# CAL0 register map
Vendor: Texas Instruments
Registers are 32-bit, read-write, reset 0x0 unless marked. A register's access mark holds for its fields unless they carry their own. Offsets are as the file gives them; [hi:lo] are bit positions; {n}, {i} and the like mark numbered series.

## CAL0 (part 2 of 2)
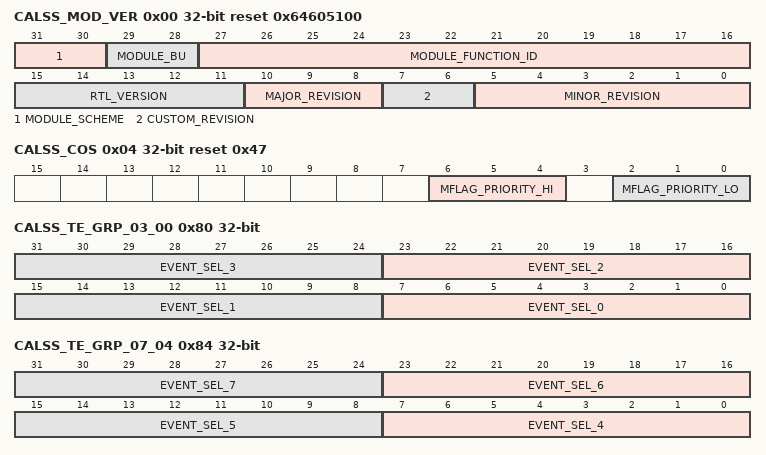
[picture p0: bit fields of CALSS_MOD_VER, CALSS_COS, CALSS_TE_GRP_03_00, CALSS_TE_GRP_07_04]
0x00 CALSS_MOD_VER ro reset 0x64605100 — The Module and Version Register identifies the module identifier and CAL_REVISION of the CAL module.
  [31:30] MODULE_SCHEME — CAL module Scheme
  [29:28] MODULE_BU — CAL module Bussiness Unit
  [27:16] MODULE_FUNCTION_ID — CAL module ID.
  [15:11] RTL_VERSION
  [10:8] MAJOR_REVISION
  [7:6] CUSTOM_REVISION
  [5:0] MINOR_REVISION
0x04 CALSS_COS reset 0x47 — The Class of Service register is used to set the priority of master transactions based on the state of ~imflag.
  [6:4] MFLAG_PRIORITY_HI — CAL Master hi priority value when mflag is set.
  [2:0] MFLAG_PRIORITY_LO — CAL Master low priority value when mflag is not set.
0x08 CALSS_VID_MUX_CTRL — Updated CALSS_VID_MUX_CTRL Register The Video Mux Control manages the video mux
  [2:0] BYS_MUX_SEL — CAL BYS in video mux control 4 - Selects LVDSRX output 1 7 - Selects LVDSRX output 4 Others - Reserved
0x18 CALSS_MODE reset 0x1 — The CAL Mode register controls CAL operational mode.
  [0] BASELINE_MODE — The BASELINE_MODE bit selects CAL operational mode. 0: Selects CAL full operational mode (YUV422 to YUV422BP conversion option enabled) 1: Selects CAL baseline mode (YUV422 to YUV422BP conversion option disabled)
0x80 CALSS_TE_GRP_03_00 — The Trace Event Group registers contains the Trace Event selection for a particular Trace Event group.
  [8n+7:8n] EVENT_SEL_{n} (n=0..3) — This field describes which Trace Event will be sent to trace_events[{n}]. See trace events for more info.
0x84 CALSS_TE_GRP_07_04 — The Trace Event Group registers contains the Trace Event selection for a particular Trace Event group.
  [8n-25:8n-32] EVENT_SEL_{n} (n=4..7) — This field describes which Trace Event will be sent to trace_events[{n}]. See trace events for more info.
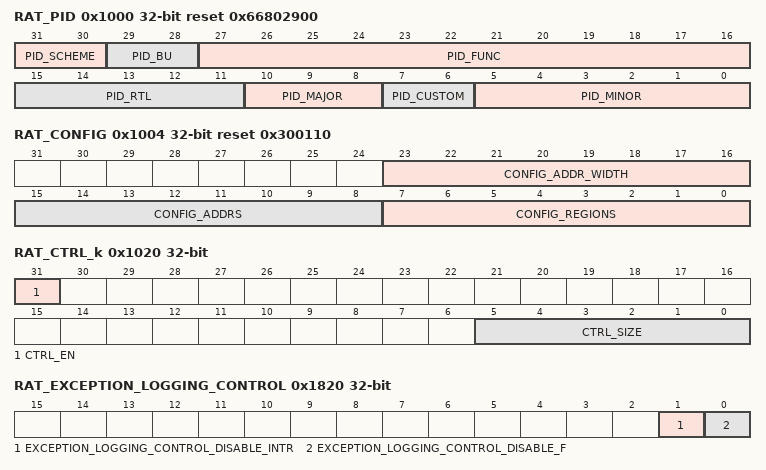
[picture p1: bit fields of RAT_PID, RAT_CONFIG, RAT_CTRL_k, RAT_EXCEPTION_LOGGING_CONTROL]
0x1000 RAT_PID ro reset 0x66802900 — The Revision Register contains the major and minor revisions for the module.
  [31:30] PID_SCHEME — PID register scheme
  [29:28] PID_BU — Business Unit: 10 = Processors
  [27:16] PID_FUNC — Module ID
  [15:11] PID_RTL — RTL REVISION. Will vary depending on release.
  [10:8] PID_MAJOR — Major REVISION
  [7:6] PID_CUSTOM — Custom
  [5:0] PID_MINOR — Minor REVISION
0x1004 RAT_CONFIG ro reset 0x300110 — The Config Register contains the configuration values for the module.
  [23:16] CONFIG_ADDR_WIDTH — Number of address bits
  [15:8] CONFIG_ADDRS — Number of addresses
  [7:0] CONFIG_REGIONS — Number of regions
0x1020 RAT_CTRL_k — The Control for Region a Offset = 1020h + (k * 10h); where k = 0h to Fh
  [31] CTRL_EN — Enable for the Region
  [5:0] CTRL_SIZE — Size of the Region in Address Bits. 0 = 1 byte, 1 = 2B, 2 = 4B, 3 = 8B, etc. up to 32 = 4GB.
0x1024 RAT_BASE_k — The Base Address for Region a. This is the source address for matching to a region. Offset = 1024h + (k * 10h); where k = 0h to Fh
  [31:0] BASE_BASE — Base Address for the Region. It must be aligned to the programmed size.
0x1028 RAT_TRANS_L_k — The Translated Lower Address Bits for Region a Offset = 1028h + (k * 10h); where k = 0h to Fh
  [31:0] TRANS_L_LOWER — Translated Lower Address Bits for the Region. It must be aligned to the programmed size.
0x102C RAT_TRANS_U_k — The Translated Upper Address Bits for Region a Offset = 102Ch + (k * 10h); where k = 0h to Fh
  [15:0] TRANS_U_UPPER — Translated Upper Address Bits for the Region
0x1804 RAT_DESTINATION_ID — The Destination ID Register defines the destination ID value for error messages.
  [7:0] DESTINATION_ID_DEST_ID — The destination ID.
0x1820 RAT_EXCEPTION_LOGGING_CONTROL — The Exception Logging Control Register controls the exception logging.
  [1] EXCEPTION_LOGGING_CONTROL_DISABLE_INTR — Disables logging interrupt when set.
  [0] EXCEPTION_LOGGING_CONTROL_DISABLE_F — Disables logging when set.
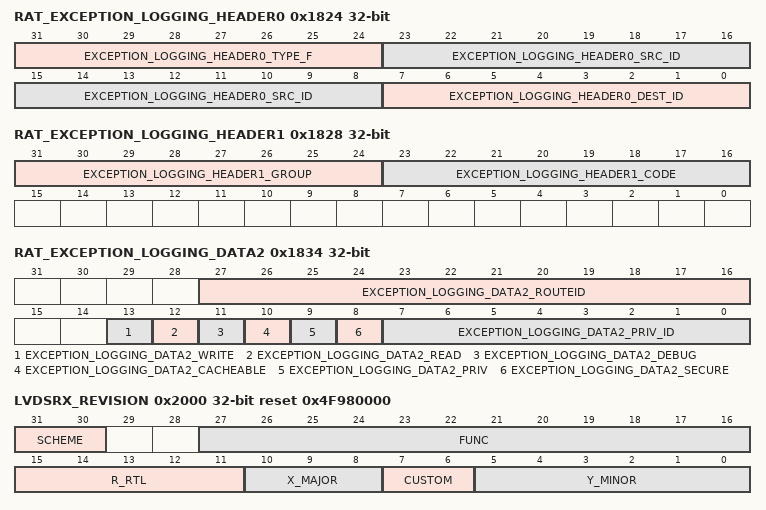
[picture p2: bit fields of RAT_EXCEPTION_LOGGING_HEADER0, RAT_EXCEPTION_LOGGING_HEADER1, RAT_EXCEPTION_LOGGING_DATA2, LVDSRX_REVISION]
0x1824 RAT_EXCEPTION_LOGGING_HEADER0 ro — The Exception Logging Header 0 Register contains the first word of the header.
  [31:24] EXCEPTION_LOGGING_HEADER0_TYPE_F — Type. 4 = RAT.
  [23:8] EXCEPTION_LOGGING_HEADER0_SRC_ID — Source ID.
  [7:0] EXCEPTION_LOGGING_HEADER0_DEST_ID — Destination ID.
0x1828 RAT_EXCEPTION_LOGGING_HEADER1 ro — The Exception Logging Header 1 Register contains the second word of the header.
  [31:24] EXCEPTION_LOGGING_HEADER1_GROUP — Group.
  [23:16] EXCEPTION_LOGGING_HEADER1_CODE — Code. 1 = Boundary crossing error.
0x182C RAT_EXCEPTION_LOGGING_DATA0 ro — The Exception Logging Data 0 Register contains the first word of the data.
  [31:0] EXCEPTION_LOGGING_DATA0_ADDR_L — Address lower 32 bits.
0x1830 RAT_EXCEPTION_LOGGING_DATA1 ro — The Exception Logging Data 1 Register contains the second word of the data.
  [15:0] EXCEPTION_LOGGING_DATA1_ADDR_H — Address upper 12 bits.
0x1834 RAT_EXCEPTION_LOGGING_DATA2 ro — The Exception Logging Data 2 Register contains the third word of the data.
  [27:16] EXCEPTION_LOGGING_DATA2_ROUTEID — Route ID.
  [13] EXCEPTION_LOGGING_DATA2_WRITE — Write.
  [12] EXCEPTION_LOGGING_DATA2_READ — Read.
  [11] EXCEPTION_LOGGING_DATA2_DEBUG — Debug.
  [10] EXCEPTION_LOGGING_DATA2_CACHEABLE — Cacheable.
  [9] EXCEPTION_LOGGING_DATA2_PRIV — Priv.
  [8] EXCEPTION_LOGGING_DATA2_SECURE — Secure.
  [7:0] EXCEPTION_LOGGING_DATA2_PRIV_ID — Priv ID.
0x1838 RAT_EXCEPTION_LOGGING_DATA3 ro — The Exception Logging Data 3 Register contains the fourth word of the data. Reading this register will clear the error pending bit.
  [9:0] EXCEPTION_LOGGING_DATA3_BYTECNT — Byte count.
0x1840 RAT_EXCEPTION_PEND_SET access not given — The Exception Logging Interrupt Pending Set Register allows to set the pend signal.
  [0] EXCEPTION_PEND_SET_PEND_SET — Write a 1 to set the exception pend signal. (access RW1S)
0x1844 RAT_EXCEPTION_PEND_CLEAR access not given — The Exception Logging Interrupt Pending Clear Register allows to clear the pend signal.
  [0] EXCEPTION_PEND_CLEAR_PEND_CLR — Write a 1 to clear the exception pend signal. (access RW1C)
0x1848 RAT_EXCEPTION_ENABLE_SET access not given — The Exception Logging Interrupt Enable Set Register allows to set the interrupt enable signal.
  [0] EXCEPTION_ENABLE_SET_ENABLE_SET — Write a 1 to set the exception interrupt enable signal. (access RW1S)
0x184C RAT_EXCEPTION_ENABLE_CLEAR access not given — The Exception Logging Interrupt Enable Clear Register allows to clear the interrupt enable signal.
  [0] EXCEPTION_ENABLE_CLEAR_ENABLE_CLR — Write a 1 to clear the exception interrupt enable signal. (access RW1C)
0x1850 RAT_EOI_REG — EOI Register The EOI register is used to re-trigger the pulse interrupt signal to ensure that any nested interrupt events are serviced. The software interrupt handler must write to the EOI register at the end of the current interrupt processing routine, so that new events can re-trigger the pulse interrupt signal again. For level interrupt signals the EOI register is not functional and must not be used.
  [15:0] EOI_REG_EOI_WR — EOI Register
0x2000 LVDSRX_REVISION ro reset 0x4F980000
  [31:30] SCHEME — Used to distinguish between old scheme and current. RD: 0 - LEGACY : Legacy ASP or WTBU scheme RD: 1 - H08 : Highlander 0.8 scheme
  [27:16] FUNC — Function indicates a software compatible module family. If there is no level of software compatibility a new Func number (and hence REVISION) should be assigned.
  [15:11] R_RTL — RTL Version (R), maintained by IP design owner. RTL follows a numbering such as X.Y.R.Z which are explained in this table. R changes ONLY when: (1) PDS uploads occur which may have been due to spec changes (2) Bug fixes occur (3) Resets to '0' when X or Y changes. Design team has an internal 'Z' (customer invisible) number which increments on every drop that happens due to DV and RTL updates. Z resets to 0 when R increments.
  [10:8] X_MAJOR — Major Revision (X), maintained by IP specification owner. X changes ONLY when: (1) There is a major feature addition. An example would be adding Master Mode to Utopia Level2. The Func field (or Class/Type in old PID format) will remain the same. X does NOT change due to: (1) Bug fixes (2) Change in feature parameters.
  [7:6] CUSTOM — Indicates a special version for a particular device. Consequence of use may avoid use of standard Chip Support Library (CSL) / Drivers. STANDARD Non custom (standard) REVISION RD: 0 - STANDARD : Non custom (standard) REVISION
  [5:0] Y_MINOR
0x2010 LVDSRX_SYSCONFIG
  [0] RESERVED — RD: 0 - DONE : Reset done, no pending action WR: 0 - NOACTION : No action WR: 1 - RESET : Initiate software reset RD: 1 - PENDING : Reset (software or other) ongoing
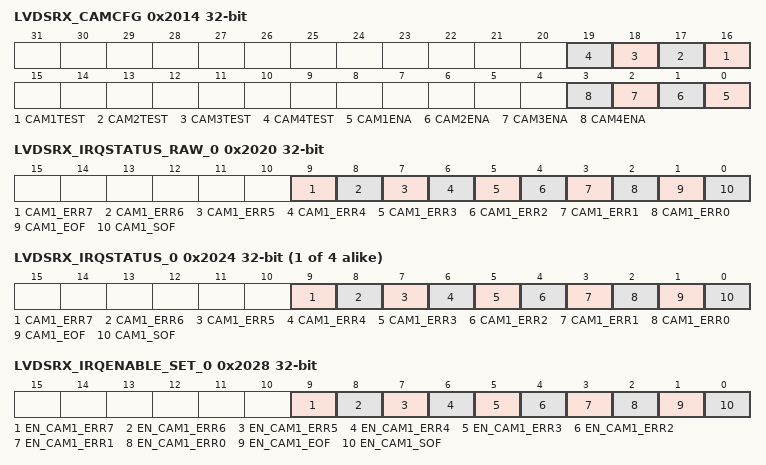
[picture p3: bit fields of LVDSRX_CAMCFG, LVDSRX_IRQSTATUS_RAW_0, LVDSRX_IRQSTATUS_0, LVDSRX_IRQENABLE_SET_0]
0x2014 LVDSRX_CAMCFG
  [n+15] CAM{n}TEST (n=1..4) — Camera port #{n} monitor
  [n-1] CAM{n}ENA (n=1..4) — Camera port #{n} control
0x201C LVDSRX_IRQ_EOI wo — The EOI register is used to re-trigger the pulse interrupt signal to ensure that any nested interrupt events are serviced. The software interrupt handler must write to the EOI register at the end of the current interrupt processing routine, so that new events can re-trigger the pulse interrupt signal again. For level interrupt signals the EOI register is not functional and must not be used.
  [2:0] LINE_NUMBER — Software End Of Interrupt (EOI) control. Write number of interrupt output to force re-evaluation of associated pending interrupts. Write n: EOI for interrupt output associated with EOI #n. WR:1 - EOI1 : EOI for interrupt output line #1 RD:0 - READ0 : Reads always 0 (no EOI memory) WR:2 - EOI2 : EOI for interrupt output line #2 WR:3 - EOI3 : EOI for interrupt output line #3 WR:4 - EOI4 : EOI for interrupt output line #4
0x2020 LVDSRX_IRQSTATUS_RAW_0 access not given
  [9] CAM1_ERR7 — sync detected timeout reached RD: 0 - NOEVENT : No event pending RD: 1 - PENDING : Event pending (access RW1S)
  [8] CAM1_ERR6 — CRC error RD: 0 - NOEVENT : No event pending RD: 1 - PENDING : Event pending (access RW1S)
  [7] CAM1_ERR5 — unexpected SOF RD: 0 - NOEVENT : No event pending RD: 1 - PENDING : Event pending (access RW1S)
  [6] CAM1_ERR4 — unexpected SOL RD: 0 - NOEVENT : No event pending RD: 1 - PENDING : Event pending (access RW1S)
  [5] CAM1_ERR3 — unexpected EOF RD: 0 - NOEVENT : No event pending RD: 1 - PENDING : Event pending (access RW1S)
  [4] CAM1_ERR2 — unexpected EOL RD: 0 - NOEVENT : No event pending RD: 1 - PENDING : Event pending (access RW1S)
  [3] CAM1_ERR1 — unexpected SOV RD: 0 - NOEVENT : No event pending RD: 1 - PENDING : Event pending (access RW1S)
  [2] CAM1_ERR0 — EOX not received RD: 0 - NOEVENT : No event pending RD: 1 - PENDING : Event pending (access RW1S)
  [1] CAM1_EOF — End of frame timing RD: 0 - NOEVENT : No event pending RD: 1 - PENDING : Event pending (access RW1S)
  [0] CAM1_SOF — Start of frame timing RD: 0 - NOEVENT : No event pending RD: 1 - PENDING : Event pending (access RW1S)
{0x2024+0x10*i} LVDSRX_IRQSTATUS_{i} access not given (i=0..3)
  [9] CAM{i+1}_ERR7 — sync detected timeout reached RD: 0 - NOEVENT : No event pending RD: 1 - PENDING : Event pending (access RW1C)
  [8] CAM{i+1}_ERR6 — CRC error RD: 0 - NOEVENT : No event pending RD: 1 - PENDING : Event pending (access RW1C)
  [7] CAM{i+1}_ERR5 — unexpected SOF RD: 0 - NOEVENT : No event pending RD: 1 - PENDING : Event pending (access RW1C)
  [6] CAM{i+1}_ERR4 — unexpected SOL RD: 0 - NOEVENT : No event pending RD: 1 - PENDING : Event pending (access RW1C)
  [5] CAM{i+1}_ERR3 — unexpected EOF RD: 0 - NOEVENT : No event pending RD: 1 - PENDING : Event pending (access RW1C)
  [4] CAM{i+1}_ERR2 — unexpected EOL RD: 0 - NOEVENT : No event pending RD: 1 - PENDING : Event pending (access RW1C)
  [3] CAM{i+1}_ERR1 — unexpected SOV RD: 0 - NOEVENT : No event pending RD: 1 - PENDING : Event pending (access RW1C)
  [2] CAM{i+1}_ERR0 — EOX not received RD: 0 - NOEVENT : No event pending RD: 1 - PENDING : Event pending (access RW1C)
  [1] CAM{i+1}_EOF — End of frame timing RD: 0 - NOEVENT : No event pending RD: 1 - PENDING : Event pending (access RW1C)
  [0] CAM{i+1}_SOF — Start of frame timing RD: 0 - NOEVENT : No event pending RD: 1 - PENDING : Event pending (access RW1C)
0x2028 LVDSRX_IRQENABLE_SET_0 access not given
  [9] EN_CAM1_ERR7 — sync detected timeout reached WR: 0 - NOACTION : No action RD: 0 - DISABLED : Interrupt disabled (masked) RD: 1 - ENABLED : Interrupt enabled WR: 1 - ENABLE : Enable interrupt (access RW1S)
  [8] EN_CAM1_ERR6 — CRC error WR: 0 - NOACTION : No action RD: 0 - DISABLED : Interrupt disabled (masked) RD: 1 - ENABLED : Interrupt enabled WR: 1 - ENABLE : Enable interrupt (access RW1S)
  [7] EN_CAM1_ERR5 — unexpected SOF WR: 0 - NOACTION : No action RD: 0 - DISABLED : Interrupt disabled (masked) RD: 1 - ENABLED : Interrupt enabled WR: 1 - ENABLE : Enable interrupt (access RW1S)
  [6] EN_CAM1_ERR4 — unexpected SOL WR: 0 - NOACTION : No action RD: 0 - DISABLED : Interrupt disabled (masked) RD: 1 - ENABLED : Interrupt enabled WR: 1 - ENABLE : Enable interrupt (access RW1S)
  [5] EN_CAM1_ERR3 — unexpected EOF WR: 0 - NOACTION : No action RD: 0 - DISABLED : Interrupt disabled (masked) RD: 1 - ENABLED : Interrupt enabled WR: 1 - ENABLE : Enable interrupt (access RW1S)
  [4] EN_CAM1_ERR2 — unexpected EOL WR: 0 - NOACTION : No action RD: 0 - DISABLED : Interrupt disabled (masked) RD: 1 - ENABLED : Interrupt enabled WR: 1 - ENABLE : Enable interrupt (access RW1S)
  [3] EN_CAM1_ERR1 — unexpected SOV WR: 0 - NOACTION : No action RD: 0 - DISABLED : Interrupt disabled (masked) RD: 1 - ENABLED : Interrupt enabled WR: 1 - ENABLE : Enable interrupt (access RW1S)
  [2] EN_CAM1_ERR0 — EOX not received WR: 0 - NOACTION : No action RD: 0 - DISABLED : Interrupt disabled (masked) RD: 1 - ENABLED : Interrupt enabled WR: 1 - ENABLE : Enable interrupt (access RW1S)
  [1] EN_CAM1_EOF — End of frame timing WR: 0 - NOACTION : No action RD: 0 - DISABLED : Interrupt disabled (masked) RD: 1 - ENABLED : Interrupt enabled WR: 1 - ENABLE : Enable interrupt (access RW1S)
  [0] EN_CAM1_SOF — Start of frame timing WR: 0 - NOACTION : No action RD: 0 - DISABLED : Interrupt disabled (masked) RD: 1 - ENABLED : Interrupt enabled WR: 1 - ENABLE : Enable interrupt (access RW1S)
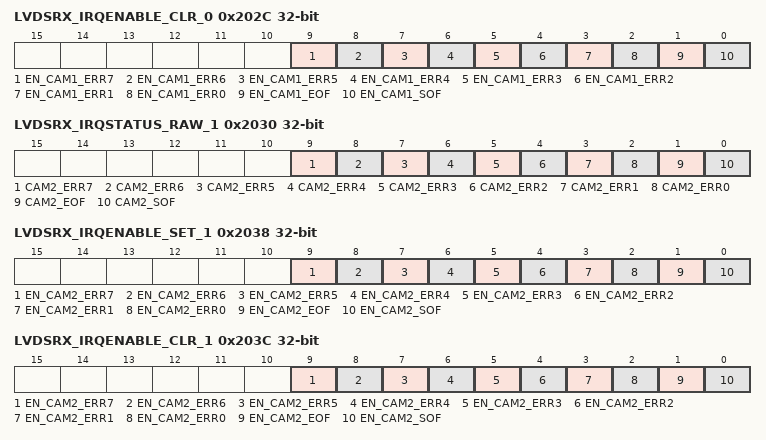
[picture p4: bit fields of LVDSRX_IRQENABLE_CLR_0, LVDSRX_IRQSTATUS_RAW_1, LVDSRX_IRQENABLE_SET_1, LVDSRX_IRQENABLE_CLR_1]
0x202C LVDSRX_IRQENABLE_CLR_0 access not given
  [9] EN_CAM1_ERR7 — sync detected timeout reached WR: 0 - NOACTION : No action RD: 0 - DISABLED : Interrupt disabled (masked) RD: 1 - ENABLED : Interrupt enabled WR: 1 - DISABLE : Disable interrupt (access RW1C)
  [8] EN_CAM1_ERR6 — CRC error WR: 0 - NOACTION : No action RD: 0 - DISABLED : Interrupt disabled (masked) RD: 1 - ENABLED : Interrupt enabled WR: 1 - DISABLE : Disable interrupt (access RW1C)
  [7] EN_CAM1_ERR5 — unexpected SOF WR: 0 - NOACTION : No action RD: 0 - DISABLED : Interrupt disabled (masked) RD: 1 - ENABLED : Interrupt enabled WR: 1 - DISABLE : Disable interrupt (access RW1C)
  [6] EN_CAM1_ERR4 — unexpected SOL WR: 0 - NOACTION : No action RD: 0 - DISABLED : Interrupt disabled (masked) RD: 1 - ENABLED : Interrupt enabled WR: 1 - DISABLE : Disable interrupt (access RW1C)
  [5] EN_CAM1_ERR3 — unexpected EOF WR: 0 - NOACTION : No action RD: 0 - DISABLED : Interrupt disabled (masked) RD: 1 - ENABLED : Interrupt enabled WR: 1 - DISABLE : Disable interrupt (access RW1C)
  [4] EN_CAM1_ERR2 — unexpected EOL WR: 0 - NOACTION : No action RD: 0 - DISABLED : Interrupt disabled (masked) RD: 1 - ENABLED : Interrupt enabled WR: 1 - DISABLE : Disable interrupt (access RW1C)
  [3] EN_CAM1_ERR1 — unexpected SOV WR: 0 - NOACTION : No action RD: 0 - DISABLED : Interrupt disabled (masked) RD: 1 - ENABLED : Interrupt enabled WR: 1 - DISABLE : Disable interrupt (access RW1C)
  [2] EN_CAM1_ERR0 — EOX not received WR: 0 - NOACTION : No action RD: 0 - DISABLED : Interrupt disabled (masked) RD: 1 - ENABLED : Interrupt enabled WR: 1 - DISABLE : Disable interrupt (access RW1C)
  [1] EN_CAM1_EOF — End of frame timing WR: 0 - NOACTION : No action RD: 0 - DISABLED : Interrupt disabled (masked) RD: 1 - ENABLED : Interrupt enabled WR: 1 - DISABLE : Disable interrupt (access RW1C)
  [0] EN_CAM1_SOF — Start of frame timing WR: 0 - NOACTION : No action RD: 0 - DISABLED : Interrupt disabled (masked) RD: 1 - ENABLED : Interrupt enabled WR: 1 - DISABLE : Disable interrupt (access RW1C)
0x2030 LVDSRX_IRQSTATUS_RAW_1 access not given
  [9] CAM2_ERR7 — sync detected timeout reached RD: 0 - NOEVENT : No event pending RD: 1 - PENDING : Event pending (access RW1S)
  [8] CAM2_ERR6 — CRC error RD: 0 - NOEVENT : No event pending RD: 1 - PENDING : Event pending (access RW1S)
  [7] CAM2_ERR5 — unexpected SOF RD: 0 - NOEVENT : No event pending RD: 1 - PENDING : Event pending (access RW1S)
  [6] CAM2_ERR4 — unexpected SOL RD: 0 - NOEVENT : No event pending RD: 1 - PENDING : Event pending (access RW1S)
  [5] CAM2_ERR3 — unexpected EOF RD: 0 - NOEVENT : No event pending RD: 1 - PENDING : Event pending (access RW1S)
  [4] CAM2_ERR2 — unexpected EOL RD: 0 - NOEVENT : No event pending RD: 1 - PENDING : Event pending (access RW1S)
  [3] CAM2_ERR1 — unexpected SOV RD: 0 - NOEVENT : No event pending RD: 1 - PENDING : Event pending (access RW1S)
  [2] CAM2_ERR0 — EOX not received RD: 0 - NOEVENT : No event pending RD: 1 - PENDING : Event pending (access RW1S)
  [1] CAM2_EOF — End of frame timing RD: 0 - NOEVENT : No event pending RD: 1 - PENDING : Event pending (access RW1S)
  [0] CAM2_SOF — Start of frame timing RD: 0 - NOEVENT : No event pending RD: 1 - PENDING : Event pending (access RW1S)
0x2038 LVDSRX_IRQENABLE_SET_1 access not given
  [9] EN_CAM2_ERR7 — sync detected timeout reached WR: 0 - NOACTION : No action RD: 0 - DISABLED : Interrupt disabled (masked) RD: 1 - ENABLED : Interrupt enabled WR: 1 - ENABLE : Enable interrupt (access RW1S)
  [8] EN_CAM2_ERR6 — CRC error WR: 0 - NOACTION : No action RD: 0 - DISABLED : Interrupt disabled (masked) RD: 1 - ENABLED : Interrupt enabled WR: 1 - ENABLE : Enable interrupt (access RW1S)
  [7] EN_CAM2_ERR5 — unexpected SOF WR: 0 - NOACTION : No action RD: 0 - DISABLED : Interrupt disabled (masked) RD: 1 - ENABLED : Interrupt enabled WR: 1 - ENABLE : Enable interrupt (access RW1S)
  [6] EN_CAM2_ERR4 — unexpected SOL WR: 0 - NOACTION : No action RD: 0 - DISABLED : Interrupt disabled (masked) RD: 1 - ENABLED : Interrupt enabled WR: 1 - ENABLE : Enable interrupt (access RW1S)
  [5] EN_CAM2_ERR3 — unexpected EOF WR: 0 - NOACTION : No action RD: 0 - DISABLED : Interrupt disabled (masked) RD: 1 - ENABLED : Interrupt enabled WR: 1 - ENABLE : Enable interrupt (access RW1S)
  [4] EN_CAM2_ERR2 — unexpected EOL WR: 0 - NOACTION : No action RD: 0 - DISABLED : Interrupt disabled (masked) RD: 1 - ENABLED : Interrupt enabled WR: 1 - ENABLE : Enable interrupt (access RW1S)
  [3] EN_CAM2_ERR1 — unexpected SOV WR: 0 - NOACTION : No action RD: 0 - DISABLED : Interrupt disabled (masked) RD: 1 - ENABLED : Interrupt enabled WR: 1 - ENABLE : Enable interrupt (access RW1S)
  [2] EN_CAM2_ERR0 — EOX not received WR: 0 - NOACTION : No action RD: 0 - DISABLED : Interrupt disabled (masked) RD: 1 - ENABLED : Interrupt enabled WR: 1 - ENABLE : Enable interrupt (access RW1S)
  [1] EN_CAM2_EOF — End of frame timing WR: 0 - NOACTION : No action RD: 0 - DISABLED : Interrupt disabled (masked) RD: 1 - ENABLED : Interrupt enabled WR: 1 - ENABLE : Enable interrupt (access RW1S)
  [0] EN_CAM2_SOF — Start of frame timing WR: 0 - NOACTION : No action RD: 0 - DISABLED : Interrupt disabled (masked) RD: 1 - ENABLED : Interrupt enabled WR: 1 - ENABLE : Enable interrupt (access RW1S)
0x203C LVDSRX_IRQENABLE_CLR_1 access not given
  [9] EN_CAM2_ERR7 — sync detected timeout reached WR: 0 - NOACTION : No action RD: 0 - DISABLED : Interrupt disabled (masked) RD: 1 - ENABLED : Interrupt enabled WR: 1 - DISABLE : Disable interrupt (access RW1C)
  [8] EN_CAM2_ERR6 — CRC error WR: 0 - NOACTION : No action RD: 0 - DISABLED : Interrupt disabled (masked) RD: 1 - ENABLED : Interrupt enabled WR: 1 - DISABLE : Disable interrupt (access RW1C)
  [7] EN_CAM2_ERR5 — unexpected SOF WR: 0 - NOACTION : No action RD: 0 - DISABLED : Interrupt disabled (masked) RD: 1 - ENABLED : Interrupt enabled WR: 1 - DISABLE : Disable interrupt (access RW1C)
  [6] EN_CAM2_ERR4 — unexpected SOL WR: 0 - NOACTION : No action RD: 0 - DISABLED : Interrupt disabled (masked) RD: 1 - ENABLED : Interrupt enabled WR: 1 - DISABLE : Disable interrupt (access RW1C)
  [5] EN_CAM2_ERR3 — unexpected EOF WR: 0 - NOACTION : No action RD: 0 - DISABLED : Interrupt disabled (masked) RD: 1 - ENABLED : Interrupt enabled WR: 1 - DISABLE : Disable interrupt (access RW1C)
  [4] EN_CAM2_ERR2 — unexpected EOL WR: 0 - NOACTION : No action RD: 0 - DISABLED : Interrupt disabled (masked) RD: 1 - ENABLED : Interrupt enabled WR: 1 - DISABLE : Disable interrupt (access RW1C)
  [3] EN_CAM2_ERR1 — unexpected SOV WR: 0 - NOACTION : No action RD: 0 - DISABLED : Interrupt disabled (masked) RD: 1 - ENABLED : Interrupt enabled WR: 1 - DISABLE : Disable interrupt (access RW1C)
  [2] EN_CAM2_ERR0 — EOX not received WR: 0 - NOACTION : No action RD: 0 - DISABLED : Interrupt disabled (masked) RD: 1 - ENABLED : Interrupt enabled WR: 1 - DISABLE : Disable interrupt (access RW1C)
  [1] EN_CAM2_EOF — End of frame timing WR: 0 - NOACTION : No action RD: 0 - DISABLED : Interrupt disabled (masked) RD: 1 - ENABLED : Interrupt enabled WR: 1 - DISABLE : Disable interrupt (access RW1C)
  [0] EN_CAM2_SOF — Start of frame timing WR: 0 - NOACTION : No action RD: 0 - DISABLED : Interrupt disabled (masked) RD: 1 - ENABLED : Interrupt enabled WR: 1 - DISABLE : Disable interrupt (access RW1C)
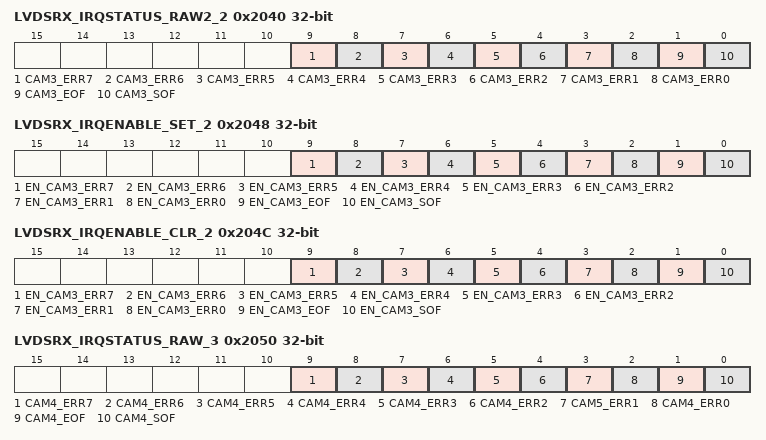
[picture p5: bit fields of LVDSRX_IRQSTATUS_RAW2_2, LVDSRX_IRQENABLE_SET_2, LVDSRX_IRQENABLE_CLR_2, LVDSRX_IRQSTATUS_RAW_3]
0x2040 LVDSRX_IRQSTATUS_RAW2_2 access not given
  [9] CAM3_ERR7 — sync detected timeout reached RD: 0 - NOEVENT : No event pending RD: 1 - PENDING : Event pending (access RW1S)
  [8] CAM3_ERR6 — CRC error RD: 0 - NOEVENT : No event pending RD: 1 - PENDING : Event pending (access RW1S)
  [7] CAM3_ERR5 — unexpected SOF RD: 0 - NOEVENT : No event pending RD: 1 - PENDING : Event pending (access RW1S)
  [6] CAM3_ERR4 — unexpected SOL RD: 0 - NOEVENT : No event pending RD: 1 - PENDING : Event pending (access RW1S)
  [5] CAM3_ERR3 — unexpected EOF RD: 0 - NOEVENT : No event pending RD: 1 - PENDING : Event pending (access RW1S)
  [4] CAM3_ERR2 — unexpected EOL RD: 0 - NOEVENT : No event pending RD: 1 - PENDING : Event pending (access RW1S)
  [3] CAM3_ERR1 — unexpected SOV RD: 0 - NOEVENT : No event pending RD: 1 - PENDING : Event pending (access RW1S)
  [2] CAM3_ERR0 — EOX not received RD: 0 - NOEVENT : No event pending RD: 1 - PENDING : Event pending (access RW1S)
  [1] CAM3_EOF — End of frame timing RD: 0 - NOEVENT : No event pending RD: 1 - PENDING : Event pending (access RW1S)
  [0] CAM3_SOF — Start of frame timing RD: 0 - NOEVENT : No event pending RD: 1 - PENDING : Event pending (access RW1S)
0x2048 LVDSRX_IRQENABLE_SET_2 access not given
  [9] EN_CAM3_ERR7 — sync detected timeout reached WR: 0 - NOACTION : No action RD: 0 - DISABLED : Interrupt disabled (masked) RD: 1 - ENABLED : Interrupt enabled WR: 1 - ENABLE : Enable interrupt (access RW1S)
  [8] EN_CAM3_ERR6 — CRC error WR: 0 - NOACTION : No action RD: 0 - DISABLED : Interrupt disabled (masked) RD: 1 - ENABLED : Interrupt enabled WR: 1 - ENABLE : Enable interrupt (access RW1S)
  [7] EN_CAM3_ERR5 — unexpected SOF WR: 0 - NOACTION : No action RD: 0 - DISABLED : Interrupt disabled (masked) RD: 1 - ENABLED : Interrupt enabled WR: 1 - ENABLE : Enable interrupt (access RW1S)
  [6] EN_CAM3_ERR4 — unexpected SOL WR: 0 - NOACTION : No action RD: 0 - DISABLED : Interrupt disabled (masked) RD: 1 - ENABLED : Interrupt enabled WR: 1 - ENABLE : Enable interrupt (access RW1S)
  [5] EN_CAM3_ERR3 — unexpected EOF WR: 0 - NOACTION : No action RD: 0 - DISABLED : Interrupt disabled (masked) RD: 1 - ENABLED : Interrupt enabled WR: 1 - ENABLE : Enable interrupt (access RW1S)
  [4] EN_CAM3_ERR2 — unexpected EOL WR: 0 - NOACTION : No action RD: 0 - DISABLED : Interrupt disabled (masked) RD: 1 - ENABLED : Interrupt enabled WR: 1 - ENABLE : Enable interrupt (access RW1S)
  [3] EN_CAM3_ERR1 — unexpected SOV WR: 0 - NOACTION : No action RD: 0 - DISABLED : Interrupt disabled (masked) RD: 1 - ENABLED : Interrupt enabled WR: 1 - ENABLE : Enable interrupt (access RW1S)
  [2] EN_CAM3_ERR0 — EOX not received WR: 0 - NOACTION : No action RD: 0 - DISABLED : Interrupt disabled (masked) RD: 1 - ENABLED : Interrupt enabled WR: 1 - ENABLE : Enable interrupt (access RW1S)
  [1] EN_CAM3_EOF — End of frame timing RD: 0 - NOEVENT : No event pending RD: 1 - PENDING : Event pending (access RW1S)
  [0] EN_CAM3_SOF — Start of frame timing WR: 0 - NOACTION : No action RD: 0 - DISABLED : Interrupt disabled (masked) RD: 1 - ENABLED : Interrupt enabled WR: 1 - ENABLE : Enable interrupt (access RW1S)
0x204C LVDSRX_IRQENABLE_CLR_2 access not given
  [9] EN_CAM3_ERR7 — sync detected timeout reached WR: 0 - NOACTION : No action RD: 0 - DISABLED : Interrupt disabled (masked) RD: 1 - ENABLED : Interrupt enabled WR: 1 - DISABLE : Disable interrupt (access RW1C)
  [8] EN_CAM3_ERR6 — CRC error WR: 0 - NOACTION : No action RD: 0 - DISABLED : Interrupt disabled (masked) RD: 1 - ENABLED : Interrupt enabled WR: 1 - DISABLE : Disable interrupt (access RW1C)
  [7] EN_CAM3_ERR5 — unexpected SOF WR: 0 - NOACTION : No action RD: 0 - DISABLED : Interrupt disabled (masked) RD: 1 - ENABLED : Interrupt enabled WR: 1 - DISABLE : Disable interrupt (access RW1C)
  [6] EN_CAM3_ERR4 — unexpected SOL WR: 0 - NOACTION : No action RD: 0 - DISABLED : Interrupt disabled (masked) RD: 1 - ENABLED : Interrupt enabled WR: 1 - DISABLE : Disable interrupt (access RW1C)
  [5] EN_CAM3_ERR3 — unexpected EOF WR: 0 - NOACTION : No action RD: 0 - DISABLED : Interrupt disabled (masked) RD: 1 - ENABLED : Interrupt enabled WR: 1 - DISABLE : Disable interrupt (access RW1C)
  [4] EN_CAM3_ERR2 — unexpected EOL WR: 0 - NOACTION : No action RD: 0 - DISABLED : Interrupt disabled (masked) RD: 1 - ENABLED : Interrupt enabled WR: 1 - DISABLE : Disable interrupt (access RW1C)
  [3] EN_CAM3_ERR1 — unexpected SOV WR: 0 - NOACTION : No action RD: 0 - DISABLED : Interrupt disabled (masked) RD: 1 - ENABLED : Interrupt enabled WR: 1 - DISABLE : Disable interrupt (access RW1C)
  [2] EN_CAM3_ERR0 — EOX not received WR: 0 - NOACTION : No action RD: 0 - DISABLED : Interrupt disabled (masked) RD: 1 - ENABLED : Interrupt enabled WR: 1 - DISABLE : Disable interrupt (access RW1C)
  [1] EN_CAM3_EOF — End of frame timing RD: 0 - NOEVENT : No event pending RD: 1 - PENDING : Event pending (access RW1C)
  [0] EN_CAM3_SOF — Start of frame timing WR: 0 - NOACTION : No action RD: 0 - DISABLED : Interrupt disabled (masked) RD: 1 - ENABLED : Interrupt enabled WR: 1 - DISABLE : Disable interrupt (access RW1C)
0x2050 LVDSRX_IRQSTATUS_RAW_3 access not given
  [9] CAM4_ERR7 — sync detected timeout reached RD: 0 - NOEVENT : No event pending RD: 1 - PENDING : Event pending (access RW1S)
  [8] CAM4_ERR6 — CRC error RD: 0 - NOEVENT : No event pending RD: 1 - PENDING : Event pending (access RW1S)
  [7] CAM4_ERR5 — unexpected SOF RD: 0 - NOEVENT : No event pending RD: 1 - PENDING : Event pending (access RW1S)
  [6] CAM4_ERR4 — unexpected SOL RD: 0 - NOEVENT : No event pending RD: 1 - PENDING : Event pending (access RW1S)
  [5] CAM4_ERR3 — unexpected EOF RD: 0 - NOEVENT : No event pending RD: 1 - PENDING : Event pending (access RW1S)
  [4] CAM4_ERR2 — unexpected EOL RD: 0 - NOEVENT : No event pending RD: 1 - PENDING : Event pending (access RW1S)
  [3] CAM5_ERR1 — unexpected SOV RD: 0 - NOEVENT : No event pending RD: 1 - PENDING : Event pending (access RW1S)
  [2] CAM4_ERR0 — EOX not received RD: 0 - NOEVENT : No event pending RD: 1 - PENDING : Event pending (access RW1S)
  [1] CAM4_EOF — End of frame timing RD: 0 - NOEVENT : No event pending RD: 1 - PENDING : Event pending (access RW1S)
  [0] CAM4_SOF — Start of frame timing RD: 0 - NOEVENT : No event pending RD: 1 - PENDING : Event pending (access RW1S)
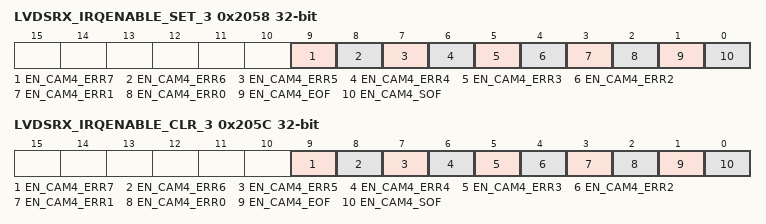
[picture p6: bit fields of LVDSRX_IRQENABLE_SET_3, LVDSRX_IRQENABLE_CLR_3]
0x2058 LVDSRX_IRQENABLE_SET_3 access not given
  [9] EN_CAM4_ERR7 — sync detected timeout reached WR: 0 - NOACTION : No action RD: 0 - DISABLED : Interrupt disabled (masked) RD: 1 - ENABLED : Interrupt enabled WR: 1 - ENABLE : Enable interrupt (access RW1S)
  [8] EN_CAM4_ERR6 — CRC error WR: 0 - NOACTION : No action RD: 0 - DISABLED : Interrupt disabled (masked) RD: 1 - ENABLED : Interrupt enabled WR: 1 - ENABLE : Enable interrupt (access RW1S)
  [7] EN_CAM4_ERR5 — unexpected SOF WR: 0 - NOACTION : No action RD: 0 - DISABLED : Interrupt disabled (masked) RD: 1 - ENABLED : Interrupt enabled WR: 1 - ENABLE : Enable interrupt (access RW1S)
  [6] EN_CAM4_ERR4 — unexpected SOL WR: 0 - NOACTION : No action RD: 0 - DISABLED : Interrupt disabled (masked) RD: 1 - ENABLED : Interrupt enabled WR: 1 - ENABLE : Enable interrupt (access RW1S)
  [5] EN_CAM4_ERR3 — unexpected EOF WR: 0 - NOACTION : No action RD: 0 - DISABLED : Interrupt disabled (masked) RD: 1 - ENABLED : Interrupt enabled WR: 1 - ENABLE : Enable interrupt (access RW1S)
  [4] EN_CAM4_ERR2 — unexpected EOL WR: 0 - NOACTION : No action RD: 0 - DISABLED : Interrupt disabled (masked) RD: 1 - ENABLED : Interrupt enabled WR: 1 - ENABLE : Enable interrupt (access RW1S)
  [3] EN_CAM4_ERR1 — unexpected SOV WR: 0 - NOACTION : No action RD: 0 - DISABLED : Interrupt disabled (masked) RD: 1 - ENABLED : Interrupt enabled WR: 1 - ENABLE : Enable interrupt (access RW1S)
  [2] EN_CAM4_ERR0 — EOX not received WR: 0 - NOACTION : No action RD: 0 - DISABLED : Interrupt disabled (masked) RD: 1 - ENABLED : Interrupt enabled WR: 1 - ENABLE : Enable interrupt (access RW1S)
  [1] EN_CAM4_EOF — End of frame timing WR: 0 - NOACTION : No action RD: 0 - DISABLED : Interrupt disabled (masked) RD: 1 - ENABLED : Interrupt enabled WR: 1 - ENABLE : Enable interrupt (access RW1S)
  [0] EN_CAM4_SOF — Start of frame timing WR: 0 - NOACTION : No action RD: 0 - DISABLED : Interrupt disabled (masked) RD: 1 - ENABLED : Interrupt enabled WR: 1 - ENABLE : Enable interrupt (access RW1S)
0x205C LVDSRX_IRQENABLE_CLR_3 access not given
  [9] EN_CAM4_ERR7 — sync detected timeout reached WR: 0 - NOACTION : No action RD: 0 - DISABLED : Interrupt disabled (masked) RD: 1 - ENABLED : Interrupt enabled WR: 1 - DISABLE : Disable interrupt (access RW1C)
  [8] EN_CAM4_ERR6 — CRC error WR: 0 - NOACTION : No action RD: 0 - DISABLED : Interrupt disabled (masked) RD: 1 - ENABLED : Interrupt enabled WR: 1 - DISABLE : Disable interrupt (access RW1C)
  [7] EN_CAM4_ERR5 — unexpected SOF WR: 0 - NOACTION : No action RD: 0 - DISABLED : Interrupt disabled (masked) RD: 1 - ENABLED : Interrupt enabled WR: 1 - DISABLE : Disable interrupt (access RW1C)
  [6] EN_CAM4_ERR4 — unexpected SOL WR: 0 - NOACTION : No action RD: 0 - DISABLED : Interrupt disabled (masked) RD: 1 - ENABLED : Interrupt enabled WR: 1 - DISABLE : Disable interrupt (access RW1C)
  [5] EN_CAM4_ERR3 — unexpected EOF WR: 0 - NOACTION : No action RD: 0 - DISABLED : Interrupt disabled (masked) RD: 1 - ENABLED : Interrupt enabled WR: 1 - DISABLE : Disable interrupt (access RW1C)
  [4] EN_CAM4_ERR2 — unexpected EOL WR: 0 - NOACTION : No action RD: 0 - DISABLED : Interrupt disabled (masked) RD: 1 - ENABLED : Interrupt enabled WR: 1 - DISABLE : Disable interrupt (access RW1C)
  [3] EN_CAM4_ERR1 — unexpected SOV WR: 0 - NOACTION : No action RD: 0 - DISABLED : Interrupt disabled (masked) RD: 1 - ENABLED : Interrupt enabled WR: 1 - DISABLE : Disable interrupt (access RW1C)
  [2] EN_CAM4_ERR0 — EOX not received WR: 0 - NOACTION : No action RD: 0 - DISABLED : Interrupt disabled (masked) RD: 1 - ENABLED : Interrupt enabled WR: 1 - DISABLE : Disable interrupt (access RW1C)
  [1] EN_CAM4_EOF — End of frame timing WR: 0 - NOACTION : No action RD: 0 - DISABLED : Interrupt disabled (masked) RD: 1 - ENABLED : Interrupt enabled WR: 1 - DISABLE : Disable interrupt (access RW1C)
  [0] EN_CAM4_SOF — Start of frame timing WR: 0 - NOACTION : No action RD: 0 - DISABLED : Interrupt disabled (masked) RD: 1 - ENABLED : Interrupt enabled WR: 1 - DISABLE : Disable interrupt (access RW1C)
